# haltium_flpr register map
Vendor: Nordic Semiconductor; Series: nRFHaltium; File version: 1
Registers are 32-bit, read-write, reset 0x0 unless marked. A register's access mark holds for its fields unless they carry their own. Offsets are from the block's base; [hi:lo] are bit positions; lines under a group give offsets from that group; {n}, {i} and the like mark numbered series; 'fields as' and 'values as' point back to an identical list.

## GLOBAL_FICR_NS — Factory Information Configuration Registers
Base 0x0FFFE000
0x00 SOCINFO group — Unspecified
  0x00 PARTNO ro reset 0xFFFFFFFF — Part number.
    [31:0] PART
  0x04 HWREVISION ro reset 0xFFFFFFFF — Hardware revision.
    [31:0] HWREVISION — Hardvare revision.
  0x08 PRODUCTIONREVISION ro reset 0xFFFFFFFF — Production reversion.
0x0C BLE group — Unspecified
  0x00 ADDRTYPE ro reset 0xFFFFFFFF — Device address type.
    [0] TYPE
      0=Public address; 1=Random address
  {0x4+4j} ADDR[{j}] (j=0..1) ro reset 0xFFFFFFFF — Description collection: 48 bit device address.
    [31:0] ADDR — Device address [n].
  {0xC+4j} ER[{j}] (j=0..3) ro reset 0xFFFFFFFF — Description collection: Encryption Root.
    [31:0] ER — Encryption root word [n].
  {0x1C+4j} IR[{j}] (j=0..3) ro reset 0xFFFFFFFF — Description collection: Identity Root.
    [31:0] IR — Identity root word [n].
0x38 LTE group — Unspecified
  {0x0+4j} IMEI[{j}] (j=0..1) ro reset 0xFFFFFFFF — Description collection: IMEI number.
    [31:0] TYPE — IMEI
0x40 NFC group — Unspecified
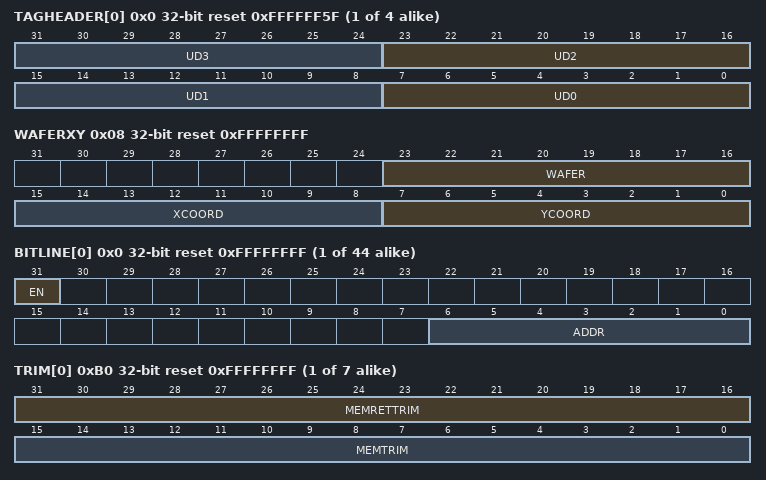
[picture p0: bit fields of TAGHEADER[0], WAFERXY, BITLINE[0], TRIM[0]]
  {0x0+4j} TAGHEADER[{j}] (j=0..3) ro reset 0xFFFFFF5F — Description collection: Default header for NFC Tag.
    [8n+7:8n] UD{n} (n=0..3) — Unique identifier byte {n}
0x50 INFO group — Device info
  0x00 CONFIGID ro reset 0xFFFFFFFF — Configuration identifier
    [15:0] HWID — Identification number for the HW
  0x04 PART ro reset 0xFFFFFFFF — Part code
    [31:0] PART
      0xFFFFFFFF=Unspecified
  0x08 VARIANT ro reset 0xFFFFFFFF — Part Variant, Hardware version and Production configuration
    [31:0] VARIANT — Part Variant, Hardware version and Production configuration, encoded as ASCII
      0xFFFFFFFF=Unspecified
  0x0C PACKAGE ro reset 0xFFFFFFFF — Package option
    [31:0] PACKAGE
      0xFFFFFFFF=Unspecified
  0x10 RAM ro reset 0xFFFFFFFF — RAM variant
    [31:0] RAM
      0xFFFFFFFF=Unspecified
  0x14 MRAM ro reset 0xFFFFFFFF — MRAM variant
    [31:0] MRAM
      0xFFFFFFFF=Unspecified
  0x18 CODEPAGESIZE ro reset 0x1000 — Code memory page size in bytes
    [31:0] CODEPAGESIZE
      0xFFFFFFFF=Unspecified
  0x1C CODESIZE ro reset 0x100 — Code memory size
    [31:0] CODESIZE — Code memory size in number of pages
      0xFFFFFFFF=Unspecified
  0x20 DEVICETYPE ro
    [31:0] DEVICETYPE
      0=Die (Device is an physical DIE); 0xFFFFFFFF=FPGA (Device is an FPGA)
0x80 PRODTEST group — Unspecified
  0x00 CP group — Unspecified
    {0x0+4k} LOTNR[{k}] (k=0..1) ro reset 0xFFFFFFFF — Description collection: Lot number.
      [31:0] LOTNR — Lot number
    0x08 WAFERXY ro reset 0xFFFFFFFF — Wafer number and die X,Y coordinate.
      [23:16] WAFER — Wafer number
      [15:8] XCOORD — Die x coordinate
      [7:0] YCOORD — Die y coordinate
    0x0C PROGVERSION1 ro reset 0xFFFFFFFF — CP1 test program version.
      [31:0] PROGVERSION1 — CP1 test program version
    0x10 PROGVERSION2 ro reset 0xFFFFFFFF — CP2 test program version.
      [31:0] PROGVERSION2 — CP2 test program version
  0x14 FT group — Unspecified
    0x00 PROGVERSION1 ro reset 0xFFFFFFFF — FT1 test program version.
      [31:0] PROGVERSION1 — FT1 test program version
    0x04 PROGVERSION2 ro reset 0xFFFFFFFF — FT2 test program version.
      [31:0] PROGVERSION2 — FT2 test program version
0x100 TRIM group — Unspecified
  0x00 GRC group — Unspecified
    0x00 FLL16M group — Unspecified
      0x00 RCOARSE ro reset 0xFFFFFFFF — Coarse Res-Trimming
        [4:0] VALUE — Res-Trimming value.
      0x04 RFINE ro reset 0xFFFFFFFF — Fine frequency trimming
        [7:0] VALUE — Fine frequency trimming value.
      0x08 TCOEF ro reset 0xFFFFFFFF — Temperature coefficient
        [7:0] VALUE
      0x0C VSUP ro reset 0xFFFFFFFF — DCO16M internal DCO supply
        [3:0] VALUE
      0x10 CKSW16MTRIM ro reset 0xFFFFFFFF — CKSW16M trim delay
        [3:0] VALUE
      0x14 CKSW16MREF ro reset 0xFFFFFFFF — CKSW16M trim reference
        [6:0] VALUE
    0x18 LFRC group — Unspecified
      0x00 LFRCOSCTRIM ro reset 0xFFFFFFFF — Initial coarse frequency trimming value for the oscillator.
        [5:0] VAL — TRIM value
    0x1C LFXO group — Unspecified
      0x00 PDLOWERTHR ro reset 0xFFFFFFFF — Peak detector lower threshold trim
        [4:0] VAL — Peak detector lower threshold trimming value
      0x04 PDUPPERTHR ro reset 0xFFFFFFFF — Peak detector upper threshold trim
        [4:0] VAL — Peak detector upper threshold trimming value
      0x08 BIAS ro reset 0xFFFFFFFF — Internal bias generator trim
        [3:0] VAL
      0x0C PIXO ro reset 0xFFFFFFFF — PIXO high pulse supply trim
        [4:0] VAL
      0x10 TRIMBUS ro reset 0xFFFFFFFF — Reserved trim bus
        [2:0] VAL — Value
    0x30 HFXO group — Unspecified
      0x00 AREG ro reset 0xFFFFFFFF — Trim for Pierce AREG mode
        [2:0] VAL — Trimming value for Pierce AREG mode
      0x04 IBIAS ro reset 0xFFFFFFFF — Internal bias generator trim
        [3:0] VAL — Internal bias generator trimming value
      0x08 PIXO ro reset 0xFFFFFFFF — PIXO high pulse supply trim
        [4:0] VAL — Trimming value
      0x0C PKD ro reset 0xFFFFFFFF — Peak detector threshold trimming
        [4:0] VAL — Peak detector threshold trimming value
      0x10 REG0V8 ro reset 0xFFFFFFFF — Trim for 0v8 regulator
        [2:0] VAL — Regulator 0v8 Trimming value
      0x14 REG1V5 ro reset 0xFFFFFFFF — Trim for 1v5 regulator
        [2:0] VAL — Regulator 1v5 Trimming value
      0x18 VREF ro reset 0xFFFFFFFF — Voltage reference trimming
        [2:0] VAL — Voltage reference trimming value
      0x1C MULT2 ro reset 0xFFFFFFFF — Trimming the duty cycle of the frequency doubler
        [3:0] VAL — Duty cycle of the frequency doubler trimming value
    0x50 AUXPLL group — Unspecified
      0x00 CTUNE ro reset 0xFFFFFFFF — Ring oscillator core process corner tuning
        [4:0] VAL — Tuning value
    0x54 MBIAS group — Unspecified
      0x00 MBIASIBPP ro reset 0xFFFFFFFF — IBPP current trimming
        [2:0] VAL — IBPP Current trimming value
      0x04 MBIASIBPSR ro reset 0xFFFFFFFF — IBPSR current and VREF voltage trimming
        [4:0] VAL — IBPSR current and VREF voltage trimming value
    0x5C OSCRFR group — Unspecified
      0x00 OSC ro reset 0xFFFFFFFF — Oscillation period trimming
        [2:0] VAL — Oscillation period trimming value
      0x04 IBPSR ro reset 0xFFFFFFFF — IBPSR current trimming
        [3:0] VAL — IBPSR current and VREF voltage trimming value
    0x64 VREG1V0 group — Unspecified
      0x00 IREF ro reset 0xFFFFFFFF — Local current reference trimming
        [6:0] VAL — Current reference trimming value
      0x04 HIGHPOWER ro reset 0xFFFFFFFF — High power mode output voltage offset trimming
        [3:0] VAL — Voltage offset trimming value
      0x08 LOWPOWER ro reset 0xFFFFFFFF — Low power mode output voltage offset trimming
        [3:0] VAL — Voltage offset trimming value.
      0x0C ULPR ro reset 0xFFFFFFFF — ULPR mode comparator offset trimming
        [2:0] VAL — Comparator offset trimming value.
    0x74 VREGAO0V8 group — Unspecified
      0x00 IREF ro reset 0xFFFFFFFF — Local current reference trimming
        [6:0] VAL — Current reference trimming value
      0x04 HIGHPOWER ro reset 0xFFFFFFFF — High power mode output voltage offset trimming
        [3:0] VAL — Voltage offset trimming value
      0x08 LOWPOWER ro reset 0xFFFFFFFF — Low power mode output voltage offset trimming
        [3:0] VAL — Voltage offset trimming value.
      0x0C ULTRALOWPOWER ro reset 0xFFFFFFFF — Ultra low power mode ripple trimming
        [1:0] VAL — Ripple trimming value.
      0x10 BPDET ro reset 0xFFFFFFFF — BP detector offset trimming
        [3:0] VAL — Voltage offset trimming value.
    0x88 VREGAO1V8 group — Unspecified
      0x00 IREF ro reset 0xFFFFFFFF — Local current reference trimming
        [6:0] VAL — Current reference trimming value
      0x04 VREF ro reset 0xFFFFFFFF — Reference voltage trim
        [3:0] VAL — Voltage trimming value
      0x08 LOWPOWER ro reset 0xFFFFFFFF — Low power mode output comparator trimming
        [2:0] VAL — Voltage trimming value.
      0x0C LOWPOWERDIFF ro reset 0xFFFFFFFF — Low power differential mode output comparator trimming
        [1:0] VAL — Voltage trimming value.
    0x98 VREGMAIN group — Unspecified
      0x00 BIASIBPP ro reset 0xFFFFFFFF — IBPP current trimming
        [2:0] VAL — Bias trim value
      0x04 BIASIBPSR ro reset 0xFFFFFFFF — IBPSR current and VREF voltage trimming
        [4:0] VAL — Bias trim value
      0x08 VDDAO1V8HYSTOUTPUT ro reset 0xFFFFFFFF — VDD_AO_1V8 hysteretic (HYST) output voltage trimming
        [3:0] VAL — Trim value
      0x0C VDDAO1V8PWMOUTPUT ro reset 0xFFFFFFFF — VDD_AO_1V8 PWM output voltage trimming
        [2:0] VAL — Trim value
      0x10 VDD1V0HYSTOUTPUT ro reset 0xFFFFFFFF — VDD_1V0 hysteretic (HYST) output voltage trimming
        [3:0] VAL — Trim value
      0x14 VDDVS0V8HYSTOUTPUT ro reset 0xFFFFFFFF — VDD_VS_0V8 hysteretic (HYST) output voltage trimming
        [3:0] VAL — Trim value
      0x18 VDDVS0V8PWMOUTPUT ro reset 0xFFFFFFFF — VDD_VS_0V8 PWM output voltage trimming
        [2:0] VAL — Trim value
      0x1C VDD1V0PWMOUTPUT ro reset 0xFFFFFFFF — VDD_1V0 PWM output voltage trimming
        [2:0] VAL — Voltage value
      0x20 ZCROSS ro reset 0xFFFFFFFF — Zero cross detector trimming
        [3:0] VAL — Trim value
      0x24 HSILIM ro reset 0xFFFFFFFF — HS current limiter trimming
        [2:0] VAL — Trim value
      0x28 ICMP ro reset 0xFFFFFFFF — DCDC output current comparator trimming
        [1:0] VAL — Trim value
    0xC4 VREGMRAM group — Unspecified
      0x00 VBG ro reset 0xFFFFFFFF — Bandgap voltage buffer trim
        [3:0] VAL — Voltage reference trimming value
      0x04 BIAS ro reset 0xFFFFFFFF — Bias trim
        [1:0] VAL — Bias trimming value
      0x08 VPR ro reset 0xFFFFFFFF — VPR reference voltage trim for 1.2V VPR
        [3:0] VAL — Voltage offset trimming value
      0x0C VREF ro reset 0xFFFFFFFF — VREF reference voltage trim for 0.6V VREF
        [3:0] VAL — Voltage offset trimming value
    0xD4 VREGVS0V8 group — Unspecified
      0x00 IREF ro reset 0xFFFFFFFF — Local current reference trimming
        [6:0] VAL — Current reference trimming value
      0x04 HIGHPOWER ro reset 0xFFFFFFFF — High power mode output voltage offset trimming
        [3:0] VAL — Voltage offset trimming value
      0x08 LOWPOWER ro reset 0xFFFFFFFF — Low power mode output voltage offset trimming
        [3:0] VAL — Voltage offset trimming value.
      0x0C ULPR ro reset 0xFFFFFFFF — ULPR mode comparator offset trimming
        [2:0] VAL — Comparator offset trimming value.
    0xE4 VDETAO0V8 group — Unspecified
      0x00 BROWNOUT ro reset 0xFFFFFFFF — Brown out detector trimming
        [2:0] VAL — Threshold voltage deviation value.
      0x04 PWRGOOD ro reset 0xFFFFFFFF — Power good detector trimming
        [2:0] VAL — Threshold voltage trimming deviation value.
    0xEC VDETAO1V8 group — Unspecified
      0x00 BROWNOUTLVLHIGH ro reset 0xFFFFFFFF — Brown out detector high threshold voltage level
        [5:0] VAL — Threshold voltage value.
      0x04 BROWNOUTLVLLOW ro reset 0xFFFFFFFF — Brown out detector low threshold voltage level
        [5:0] VAL — Threshold voltage value.
    0xF4 VDETVS0V8 group — Unspecified
      0x00 BROWNOUT ro reset 0xFFFFFFFF — Brown out detector trimming
        [2:0] VAL — Threshold voltage deviation value.
      0x04 PWRGOOD ro reset 0xFFFFFFFF — Power good detector trimming
        [2:0] VAL — Threshold voltage trimming deviation value.
  0xFC PERIPH group — Unspecified
    0x00 SAADC group — Unspecified
      0x00 CALVREF ro reset 0xFFFFFFFF — Calibration control for reference voltage
        [6:0] CALVREF — Offset binary coding
      0x04 CALGAIN ro reset 0xFFFFFFFF — Calibration control for gain error
        [6:0] CALGAIN — Offset binary coding
      0x08 CALOFFSET ro reset 0xFFFFFFFF — Calibration control for offset error
        [5:0] CALOFFSET — Sign-magnitude coding
    0x0C TEMP group — Unspecified
      0x00 A0 ro reset 0xFFFFFFFF — Slope of 1st piece wise linear function
        [11:0] A0
      0x04 A1 ro reset 0xFFFFFFFF — Slope of 2nd piece wise linear function
        [11:0] A1
      0x08 A2 ro reset 0xFFFFFFFF — Slope of 3rd piece wise linear function
        [11:0] A2
      {0x0+4l} A{l} ro reset 0xFFFFFFFF (l=3..5) — Slope of {l+1}th piece wise linear function
        [11:0] A{l}
      0x18 B0 ro reset 0xFFFFFFFF — y-intercept of 1st piece wise linear function
        [11:0] B0
      0x1C B1 ro reset 0xFFFFFFFF — y-intercept of 2nd piece wise linear function
        [11:0] B1
      0x20 B2 ro reset 0xFFFFFFFF — y-intercept of 3rd piece wise linear function
        [11:0] B2
      {0x18+4l} B{l} ro reset 0xFFFFFFFF (l=3..5) — y-intercept of {l+1}th piece wise linear function
        [11:0] B{l}
      0x30 T0 ro reset 0xFFFFFFFF — End point of 1st piece wise linear function
        [7:0] T0
      0x34 T1 ro reset 0xFFFFFFFF — End point of 2nd piece wise linear function
        [7:0] T1
      0x38 T2 ro reset 0xFFFFFFFF — End point of 3rd piece wise linear function
        [7:0] T2
      0x3C T3 ro reset 0xFFFFFFFF — End point of 4th piece wise linear function
        [7:0] T3
      0x40 T4 ro reset 0xFFFFFFFF — End point of 5th piece wise linear function
        [7:0] T4
  0x14C GD group — Unspecified
    0x00 HSFLL group — Unspecified
      0x00 VSUP ro reset 0xFFFFFFFF — Internal regulator voltage supply level trimming
        [4:0] VALUE — Trim value.
      {0x4+4l} COARSE[{l}] (l=0..3) ro reset 0xFFFFFFFF — Description collection: Coarse frequency trimming
        [9:0] VALUE — Trim value.
      {0x14+4l} FINE[{l}] (l=0..3) ro reset 0xFFFFFFFF — Description collection: Fine frequency trimming
        [10:0] VALUE — Trim value.
    0x24 MEMCONF group — Unspecified
      {0x0+4l} BITLINE[{l}] (l=0..43) ro reset 0xFFFFFFFF — Description collection: RAM repair bitline configuration RAM/ROM blocks.
        [31] EN — Enable bitline repair
        [6:0] ADDR — Repair address of the bitline
      {0xB0+4l} TRIM[{l}] (l=0..6) ro reset 0xFFFFFFFF — Description collection: Trim configuration for the RAM/ROM block types.
        [31:16] MEMRETTRIM — Trimming for retention mode for decreased leakage. Must be kept active in RAM retention mode.
        [15:0] MEMTRIM — Read/write margin trim.
  0x23C APP group — Unspecified
    0x00 ABB group — Unspecified
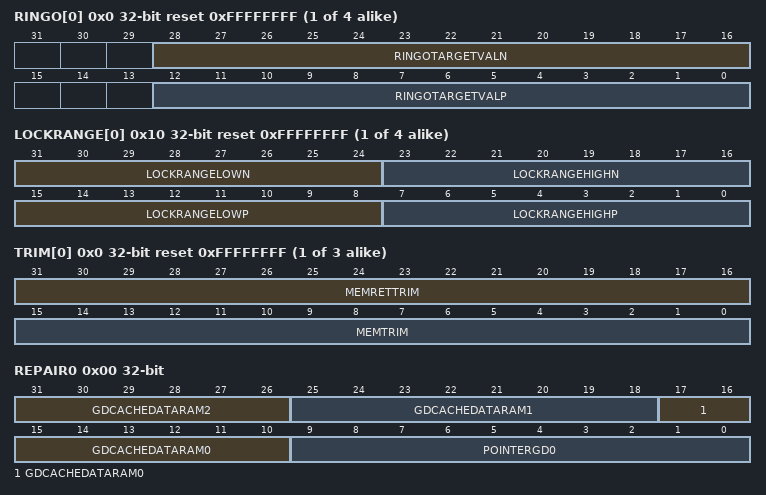
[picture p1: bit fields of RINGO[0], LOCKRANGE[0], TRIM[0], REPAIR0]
      {0x0+4l} RINGO[{l}] (l=0..3) ro reset 0xFFFFFFFF — Description collection: RINGO trim values for operation points
        [28:16] RINGOTARGETVALN — Target performance for VNW biased devices.
        [12:0] RINGOTARGETVALP — Target performance for VPW biased devices.
      {0x10+4l} LOCKRANGE[{l}] (l=0..3) ro reset 0xFFFFFFFF — Description collection: LOCKRANGE trim values for operation points
        [31:24] LOCKRANGELOWN — Lock range low boundary for VNW biased devices.
        [23:16] LOCKRANGEHIGHN — Lock range high boundary for VNW biased devices.
        [15:8] LOCKRANGELOWP — Lock range low boundary for VPW biased devices.
        [7:0] LOCKRANGEHIGHP — Lock range high boundary for VPW biased devices.
    0x20 HSFLL group — Unspecified
      0x00 VSUP ro reset 0xFFFFFFFF — Internal regulator voltage supply level trimming
        [4:0] VALUE — Trim value.
      {0x4+4l} COARSE[{l}] (l=0..9) ro reset 0xFFFFFFFF — Description collection: Coarse frequency trimming
        [9:0] VALUE — Trim value.
      {0x2C+4l} FINE[{l}] (l=0..9) ro reset 0xFFFFFFFF — Description collection: Fine frequency trimming
        [10:0] VALUE — Trim value.
    0x74 MEMCONF group — Unspecified
      {0x0+4l} TRIM[{l}] (l=0..2) ro reset 0xFFFFFFFF — Description collection: Trim configuration for the RAM/ROM block types.
        fields as TRIM.GD.MEMCONF.TRIM[0]
  0x2BC SEC group — Unspecified
    0x00 HSFLL group — Unspecified
      0x00 VSUP ro reset 0xFFFFFFFF — Internal regulator voltage supply level trimming
        [4:0] VALUE — Trim value.
      {0x4+4l} COARSE[{l}] (l=0..3) ro reset 0xFFFFFFFF — Description collection: Coarse frequency trimming
        [9:0] VALUE — Trim value.
      {0x14+4l} FINE[{l}] (l=0..3) ro reset 0xFFFFFFFF — Description collection: Fine frequency trimming
        [10:0] VALUE — Trim value.
    0x24 MEMCONF group — Unspecified
      {0x0+4l} TRIM[{l}] (l=0..6) ro reset 0xFFFFFFFF — Description collection: Trim configuration for the RAM/ROM block types.
        fields as TRIM.GD.MEMCONF.TRIM[0]
  0x2FC RADIO group — Unspecified
    0x00 HSFLL group — Unspecified
      0x00 VSUP ro reset 0xFFFFFFFF — Internal regulator voltage supply level trimming
        [4:0] VALUE — Trim value.
      0x04 COARSE ro reset 0xFFFFFFFF — Coarse frequency trimming
        [9:0] VALUE — Trim value.
      0x08 FINE ro reset 0xFFFFFFFF — Fine frequency trimming
        [10:0] VALUE — Trim value.
    0x0C MEMCONF group — Unspecified
      {0x0+4l} TRIM[{l}] (l=0..2) ro reset 0xFFFFFFFF — Description collection: Trim configuration for the RAM/ROM block types.
        fields as TRIM.GD.MEMCONF.TRIM[0]
  0x314 MIRROR ro reset 0xFFFFFFFF — Value to be written to MIRROR register in MMIs
    [31:0] MIRROR — Mirror register value
0x570 SYSCTRLROMFLOWCTRL group — Unspecified
  0x00 CHIPCONF ro reset 0xFFFFFFFF — SysCtrl ROM to apply CHIPCONF or not
    [31:0] APPLY
      0=Yes (Apply CHIPCONF (if present).); 0xFFFFFFFF=No (Do not apply CHIPCONF.)
  0x04 FACTORYPOWER ro reset 0xFFFFFFFF — SysCtrl ROM to apply default factory settings or not
    [31:0] APPLY
      0xFFFFFFFF=Yes (Apply default factory power settings.); 0=No (Do not apply default factory power settings.)
  0x08 SRAMPATCH ro reset 0xFFFFFFFF — SysCtrl ROM to patch SRAM or not
    [31:0] APPLY
      0=Yes (Apply SRAM patch information.); 0xFFFFFFFF=No (Do not apply SRAM patch information.)
0x580 BOOT group — Unspecified
  {0x8+4j} ADDRESS[{j}] (j=0..59) ro reset 0xFFFFFFFF — Description collection: Address to trim register to be loaded by SysCtrl ROM code
    [31:0] ADDRESS — Address to trim register
  {0x108+4j} DATAPOINTER[{j}] (j=0..59) ro reset 0xFFFFFFFF — Description collection: Address to location in FICR where trim value is stored
    [31:0] DATAPOINTER — Address to location in FICR where trim value is stored
0x780 SRAM group — Unspecified
  0x00 REPAIR0 — SRAM repair register 0
    [31:26] GDCACHEDATARAM2 — GD CACHEDATARAM repair bit 5 to 0
    [25:18] GDCACHEDATARAM1 — GD CACHEDATARAM repair bit 7 to 0
    [17:10] GDCACHEDATARAM0 — GD CACHEDATARAM repair bit 7 to 0
    [9:0] POINTERGD0 — Pointer to GD bit 9 to 0
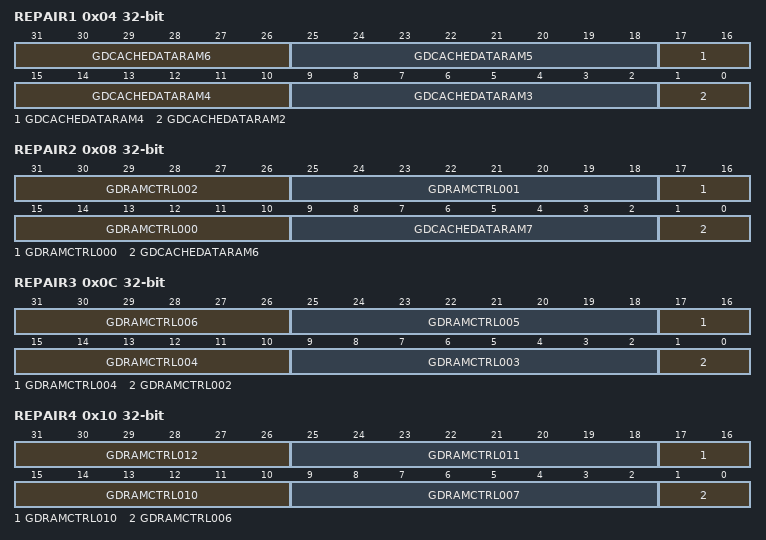
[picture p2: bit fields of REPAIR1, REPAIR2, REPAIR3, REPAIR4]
  0x04 REPAIR1 — SRAM repair register 1
    [31:26] GDCACHEDATARAM6 — GD CACHEDATARAM repair bit 5 to 0
    [25:18] GDCACHEDATARAM5 — GD CACHEDATARAM repair bit 7 to 0
    [17:10] GDCACHEDATARAM4 — GD CACHEDATARAM repair bit 7 to 0
    [9:2] GDCACHEDATARAM3 — GD CACHEDATARAM repair bit 7 to 0
    [1:0] GDCACHEDATARAM2 — GD CACHEDATARAM repair bit 7 to 6
  0x08 REPAIR2 — SRAM repair register 2
    [31:26] GDRAMCTRL002 — GD RAMCTRL00 repair bit 5 to 0
    [25:18] GDRAMCTRL001 — GD RAMCTRL00 repair bit 7 to 0
    [17:10] GDRAMCTRL000 — GD RAMCTRL00 repair bit 7 to 0
    [9:2] GDCACHEDATARAM7 — GD CACHEDATARAM repair bit 7 to 0
    [1:0] GDCACHEDATARAM6 — GD CACHEDATARAM repair bit 7 to 6
  0x0C REPAIR3 — SRAM repair register 3
    [31:26] GDRAMCTRL006 — GD RAMCTRL00 repair bit 5 to 0
    [25:18] GDRAMCTRL005 — GD RAMCTRL00 repair bit 7 to 0
    [17:10] GDRAMCTRL004 — GD RAMCTRL00 repair bit 7 to 0
    [9:2] GDRAMCTRL003 — GD RAMCTRL00 repair bit 7 to 0
    [1:0] GDRAMCTRL002 — GD RAMCTRL00 repair bit 7 to 6
  0x10 REPAIR4 — SRAM repair register 4
    [31:26] GDRAMCTRL012 — GD RAMCTRL01 repair bit 5 to 0
    [25:18] GDRAMCTRL011 — GD RAMCTRL01 repair bit 7 to 0
    [17:10] GDRAMCTRL010 — GD RAMCTRL01 repair bit 7 to 0
    [9:2] GDRAMCTRL007 — GD RAMCTRL00 repair bit 7 to 0
    [1:0] GDRAMCTRL006 — GD RAMCTRL00 repair bit 7 to 6
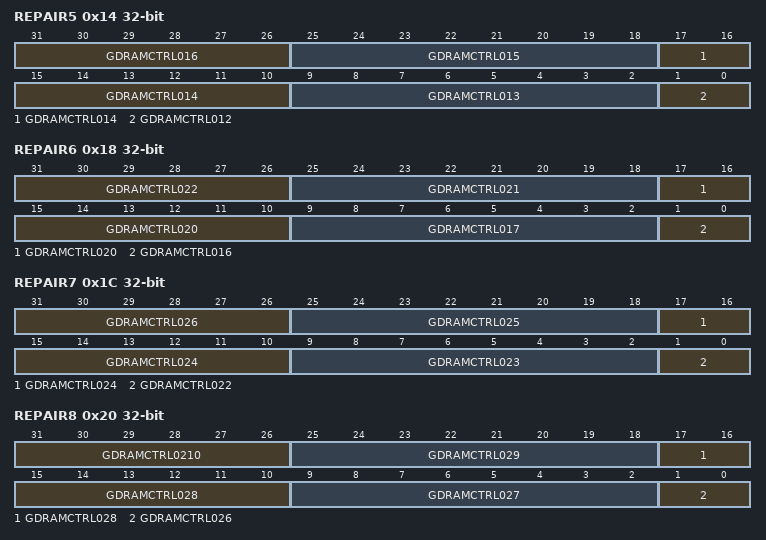
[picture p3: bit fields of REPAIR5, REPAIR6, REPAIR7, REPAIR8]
  0x14 REPAIR5 — SRAM repair register 5
    [31:26] GDRAMCTRL016 — GD RAMCTRL01 repair bit 5 to 0
    [25:18] GDRAMCTRL015 — GD RAMCTRL01 repair bit 7 to 0
    [17:10] GDRAMCTRL014 — GD RAMCTRL01 repair bit 7 to 0
    [9:2] GDRAMCTRL013 — GD RAMCTRL01 repair bit 7 to 0
    [1:0] GDRAMCTRL012 — GD RAMCTRL01 repair bit 7 to 6
  0x18 REPAIR6 — SRAM repair register 6
    [31:26] GDRAMCTRL022 — GD RAMCTRL02 repair bit 5 to 0
    [25:18] GDRAMCTRL021 — GD RAMCTRL02 repair bit 7 to 0
    [17:10] GDRAMCTRL020 — GD RAMCTRL02 repair bit 7 to 0
    [9:2] GDRAMCTRL017 — GD RAMCTRL01 repair bit 7 to 0
    [1:0] GDRAMCTRL016 — GD RAMCTRL01 repair bit 7 to 6
  0x1C REPAIR7 — SRAM repair register 7
    [31:26] GDRAMCTRL026 — GD RAMCTRL02 repair bit 5 to 0
    [25:18] GDRAMCTRL025 — GD RAMCTRL02 repair bit 7 to 0
    [17:10] GDRAMCTRL024 — GD RAMCTRL02 repair bit 7 to 0
    [9:2] GDRAMCTRL023 — GD RAMCTRL02 repair bit 7 to 0
    [1:0] GDRAMCTRL022 — GD RAMCTRL02 repair bit 7 to 6
  0x20 REPAIR8 — SRAM repair register 8
    [31:26] GDRAMCTRL0210 — GD RAMCTRL02 repair bit 5 to 0
    [25:18] GDRAMCTRL029 — GD RAMCTRL02 repair bit 7 to 0
    [17:10] GDRAMCTRL028 — GD RAMCTRL02 repair bit 7 to 0
    [9:2] GDRAMCTRL027 — GD RAMCTRL02 repair bit 7 to 0
    [1:0] GDRAMCTRL026 — GD RAMCTRL02 repair bit 7 to 6
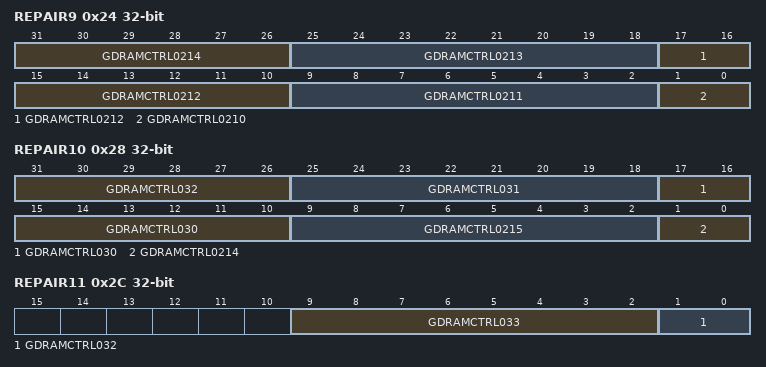
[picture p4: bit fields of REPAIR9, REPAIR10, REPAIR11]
  0x24 REPAIR9 — SRAM repair register 9
    [31:26] GDRAMCTRL0214 — GD RAMCTRL02 repair bit 5 to 0
    [25:18] GDRAMCTRL0213 — GD RAMCTRL02 repair bit 7 to 0
    [17:10] GDRAMCTRL0212 — GD RAMCTRL02 repair bit 7 to 0
    [9:2] GDRAMCTRL0211 — GD RAMCTRL02 repair bit 7 to 0
    [1:0] GDRAMCTRL0210 — GD RAMCTRL02 repair bit 7 to 6
  0x28 REPAIR10 — SRAM repair register 10
    [31:26] GDRAMCTRL032 — GD RAMCTRL03 repair bit 5 to 0
    [25:18] GDRAMCTRL031 — GD RAMCTRL03 repair bit 7 to 0
    [17:10] GDRAMCTRL030 — GD RAMCTRL03 repair bit 7 to 0
    [9:2] GDRAMCTRL0215 — GD RAMCTRL02 repair bit 7 to 0
    [1:0] GDRAMCTRL0214 — GD RAMCTRL02 repair bit 7 to 6
  0x2C REPAIR11 — SRAM repair register 11
    [9:2] GDRAMCTRL033 — GD RAMCTRL03 repair bit 7 to 0
    [1:0] GDRAMCTRL032 — GD RAMCTRL03 repair bit 7 to 6

## Notices in the file
Copyright (c) 2010 - 2021, Nordic Semiconductor ASA
All rights reserved.
Redistribution and use in source and binary forms, with or without modification,
are permitted provided that the following conditions are met:
1. Redistributions of source code must retain the above copyright notice, this
list of conditions and the following disclaimer.
2. Redistributions in binary form, except as embedded into a Nordic
Semiconductor ASA integrated circuit in a product or a software update for
such product, must reproduce the above copyright notice, this list of
conditions and the following disclaimer in the documentation and/or other
materials provided with the distribution.
3. Neither the name of Nordic Semiconductor ASA nor the names of its
contributors may be used to endorse or promote products derived from this
software without specific prior written permission.
4. This software, with or without modification, must only be used with a
Nordic Semiconductor ASA integrated circuit.
5. Any software provided in binary form under this license must not be reverse
engineered, decompiled, modified and/or disassembled.
THIS SOFTWARE IS PROVIDED BY NORDIC SEMICONDUCTOR ASA "AS IS" AND ANY EXPRESS
OR IMPLIED WARRANTIES, INCLUDING, BUT NOT LIMITED TO, THE IMPLIED WARRANTIES
OF MERCHANTABILITY, NONINFRINGEMENT, AND FITNESS FOR A PARTICULAR PURPOSE ARE
DISCLAIMED. IN NO EVENT SHALL NORDIC SEMICONDUCTOR ASA OR CONTRIBUTORS BE
LIABLE FOR ANY DIRECT, INDIRECT, INCIDENTAL, SPECIAL, EXEMPLARY, OR
CONSEQUENTIAL DAMAGES (INCLUDING, BUT NOT LIMITED TO, PROCUREMENT OF SUBSTITUTE
GOODS OR SERVICES; LOSS OF USE, DATA, OR PROFITS; OR BUSINESS INTERRUPTION)
HOWEVER CAUSED AND ON ANY THEORY OF LIABILITY, WHETHER IN CONTRACT, STRICT
LIABILITY, OR TORT (INCLUDING NEGLIGENCE OR OTHERWISE) ARISING IN ANY WAY OUT
OF THE USE OF THIS SOFTWARE, EVEN IF ADVISED OF THE POSSIBILITY OF SUCH DAMAGE.
